AUTOSAR XML (schema 4-2-2)
package /ComponentTypes
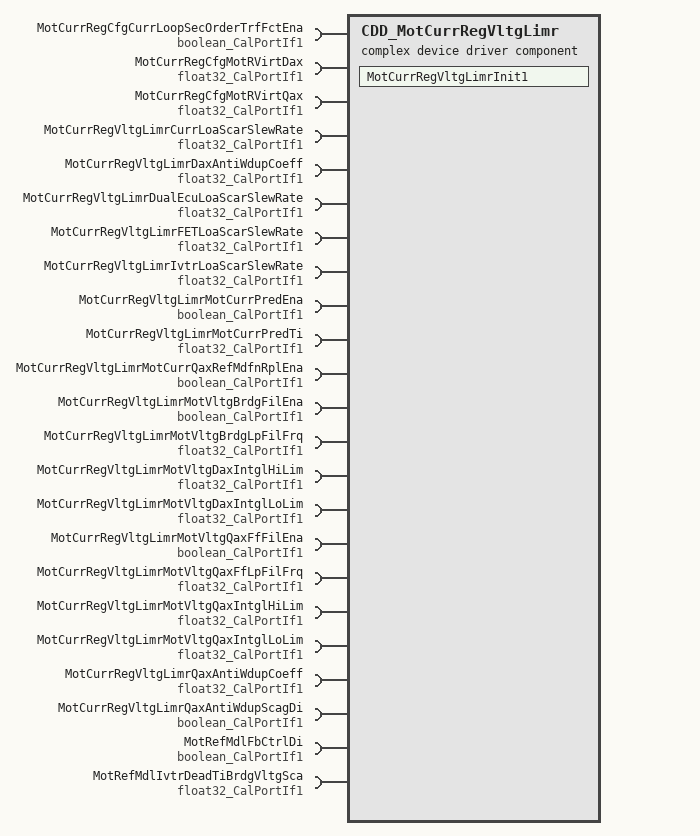
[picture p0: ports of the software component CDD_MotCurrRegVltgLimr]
  complex device driver sw component type CDD_MotCurrRegVltgLimr
    23 x require port:
      MotCurrRegCfgCurrLoopSecOrderTrfFctEna: parameter-require-com-spec{init-value=1, parameter=Logl}, required-interface=boolean_CalPortIf1
      MotCurrRegCfgMotRVirtDax: parameter-require-com-spec{init-value=0, parameter=Val}, required-interface=float32_CalPortIf1
      MotCurrRegCfgMotRVirtQax: parameter-require-com-spec{init-value=0, parameter=Val}, required-interface=float32_CalPortIf1
      MotCurrRegVltgLimrCurrLoaScarSlewRate: parameter-require-com-spec{init-value=100, parameter=Val}, required-interface=float32_CalPortIf1
      MotCurrRegVltgLimrDaxAntiWdupCoeff: parameter-require-com-spec{init-value=0, parameter=Val}, required-interface=float32_CalPortIf1
      MotCurrRegVltgLimrDualEcuLoaScarSlewRate: parameter-require-com-spec{init-value=100, parameter=Val}, required-interface=float32_CalPortIf1
      MotCurrRegVltgLimrFETLoaScarSlewRate: parameter-require-com-spec{init-value=100, parameter=Val}, required-interface=float32_CalPortIf1
      MotCurrRegVltgLimrIvtrLoaScarSlewRate: parameter-require-com-spec{init-value=100, parameter=Val}, required-interface=float32_CalPortIf1
      MotCurrRegVltgLimrMotCurrPredEna: parameter-require-com-spec{init-value=0, parameter=Logl}, required-interface=boolean_CalPortIf1
      MotCurrRegVltgLimrMotCurrPredTi: parameter-require-com-spec{init-value=0, parameter=Val}, required-interface=float32_CalPortIf1
      MotCurrRegVltgLimrMotCurrQaxRefMdfnRplEna: parameter-require-com-spec{init-value=0, parameter=Logl}, required-interface=boolean_CalPortIf1
      MotCurrRegVltgLimrMotVltgBrdgFilEna: parameter-require-com-spec{init-value=1, parameter=Logl}, required-interface=boolean_CalPortIf1
      MotCurrRegVltgLimrMotVltgBrdgLpFilFrq: parameter-require-com-spec{init-value=200, parameter=Val}, required-interface=float32_CalPortIf1
      MotCurrRegVltgLimrMotVltgDaxIntglHiLim: parameter-require-com-spec{init-value=9, parameter=Val}, required-interface=float32_CalPortIf1
      MotCurrRegVltgLimrMotVltgDaxIntglLoLim: parameter-require-com-spec{init-value=-4.5, parameter=Val}, required-interface=float32_CalPortIf1
      MotCurrRegVltgLimrMotVltgQaxFfFilEna: parameter-require-com-spec{init-value=1, parameter=Logl}, required-interface=boolean_CalPortIf1
      MotCurrRegVltgLimrMotVltgQaxFfLpFilFrq: parameter-require-com-spec{init-value=500, parameter=Val}, required-interface=float32_CalPortIf1
      MotCurrRegVltgLimrMotVltgQaxIntglHiLim: parameter-require-com-spec{init-value=14.5, parameter=Val}, required-interface=float32_CalPortIf1
      MotCurrRegVltgLimrMotVltgQaxIntglLoLim: parameter-require-com-spec{init-value=-14.5, parameter=Val}, required-interface=float32_CalPortIf1
      MotCurrRegVltgLimrQaxAntiWdupCoeff: parameter-require-com-spec{init-value=0, parameter=Val}, required-interface=float32_CalPortIf1
      MotCurrRegVltgLimrQaxAntiWdupScagDi: parameter-require-com-spec{init-value=0, parameter=Logl}, required-interface=boolean_CalPortIf1
      MotRefMdlFbCtrlDi: parameter-require-com-spec{init-value=0, parameter=Logl}, required-interface=boolean_CalPortIf1
      MotRefMdlIvtrDeadTiBrdgVltgSca: parameter-require-com-spec{init-value=1, parameter=Val}, required-interface=float32_CalPortIf1
    behavior CDD_MotCurrRegVltgLimr_InternalBehavior: data-type-mapping=Nexteer
      ar-typed-per-instance-memorys:
        39 x data, all with sw-calibration-access=READ-ONLY:
          AntiWdupCmdScaDax: type=float32
          AntiWdupCmdScaQax: type=float32
          CurrLoaScarPrev: type=float32
          dMotCurrRegVltgLimrAntiWdupCmdScaDax: type=float32
          dMotCurrRegVltgLimrAntiWdupCmdScaQax: type=float32
          dMotCurrRegVltgLimrMotCurrCmdErrDax: type=float32
          dMotCurrRegVltgLimrMotCurrCmdErrQax: type=float32
          dMotCurrRegVltgLimrMotCurrCmdScaDax: type=float32
          dMotCurrRegVltgLimrMotCurrCmdScaQax: type=float32
          dMotCurrRegVltgLimrMotVltgBrdgFild: type=float32
          dMotCurrRegVltgLimrMotVltgCmdFinal: type=float32
          dMotCurrRegVltgLimrMotVltgCmdPreLim: type=float32
          dMotCurrRegVltgLimrMotVltgDampgDax: type=float32
          dMotCurrRegVltgLimrMotVltgDampgQax: type=float32
          dMotCurrRegVltgLimrMotVltgDaxFb: type=float32
          dMotCurrRegVltgLimrMotVltgDaxIntglPreLim: type=float32
          dMotCurrRegVltgLimrMotVltgDecoupldFbDax: type=float32
          dMotCurrRegVltgLimrMotVltgDecoupldFbQax: type=float32
          dMotCurrRegVltgLimrMotVltgDircFbDax: type=float32
          dMotCurrRegVltgLimrMotVltgDircFbQax: type=float32
          dMotCurrRegVltgLimrMotVltgPreLimDax: type=float32
          dMotCurrRegVltgLimrMotVltgPreLimQax: type=float32
          dMotCurrRegVltgLimrMotVltgPropCmdDax: type=float32
          dMotCurrRegVltgLimrMotVltgPropCmdQax: type=float32
          dMotCurrRegVltgLimrMotVltgQaxFb: type=float32
          dMotCurrRegVltgLimrMotVltgQaxFfFild: type=float32
          dMotCurrRegVltgLimrMotVltgQaxIntglPreLim: type=float32
          dMotCurrRegVltgLimrMotVltgSatnIvsRat: type=float32
          dMotCurrRegVltgLimrMotVltgSatnRat: type=float32
          dMotCurrRegVltgLimrPhaAdvPreDly: type=float32
          DualEcuLoaScarPrev: type=float32
          FETLoaScarPrev: type=float32
          IvtrLoaScarPrev: type=float32
          MotCtrlMotVltgDaxPrev: type=float32
          MotCtrlMotVltgQaxPrev: type=float32
          MotVltgBrdgLpFil: type=FilLpRec1
          MotVltgIntglCmdDaxPrev: type=float32
          MotVltgIntglCmdQaxPrev: type=float32
          MotVltgQaxFfLpFil: type=FilLpRec1
      init event MotCurrRegVltgLimrInit1_InitEvent: start-on-event=MotCurrRegVltgLimrInit1
      port-api-options:
        enable-take-address=false, error-handling=NO-TRANSFORMER-ERROR-HANDLING, indirect-api=false, port=MotCurrRegCfgCurrLoopSecOrderTrfFctEna
        enable-take-address=false, error-handling=NO-TRANSFORMER-ERROR-HANDLING, indirect-api=false, port=MotCurrRegCfgMotRVirtQax
        enable-take-address=false, error-handling=NO-TRANSFORMER-ERROR-HANDLING, indirect-api=false, port=MotCurrRegVltgLimrCurrLoaScarSlewRate
        enable-take-address=false, error-handling=NO-TRANSFORMER-ERROR-HANDLING, indirect-api=false, port=MotCurrRegVltgLimrDaxAntiWdupCoeff
        enable-take-address=false, error-handling=NO-TRANSFORMER-ERROR-HANDLING, indirect-api=false, port=MotCurrRegVltgLimrDualEcuLoaScarSlewRate
        enable-take-address=false, error-handling=NO-TRANSFORMER-ERROR-HANDLING, indirect-api=false, port=MotCurrRegVltgLimrIvtrLoaScarSlewRate
        enable-take-address=false, error-handling=NO-TRANSFORMER-ERROR-HANDLING, indirect-api=false, port=MotCurrRegVltgLimrMotCurrPredEna
        enable-take-address=false, error-handling=NO-TRANSFORMER-ERROR-HANDLING, indirect-api=false, port=MotCurrRegVltgLimrMotCurrQaxRefMdfnRplEna
        enable-take-address=false, error-handling=NO-TRANSFORMER-ERROR-HANDLING, indirect-api=false, port=MotCurrRegVltgLimrMotVltgBrdgFilEna
        enable-take-address=false, error-handling=NO-TRANSFORMER-ERROR-HANDLING, indirect-api=false, port=MotCurrRegVltgLimrMotVltgBrdgLpFilFrq
        enable-take-address=false, error-handling=NO-TRANSFORMER-ERROR-HANDLING, indirect-api=false, port=MotCurrRegVltgLimrMotVltgDaxIntglHiLim
        enable-take-address=false, error-handling=NO-TRANSFORMER-ERROR-HANDLING, indirect-api=false, port=MotRefMdlIvtrDeadTiBrdgVltgSca
      runnable MotCurrRegVltgLimrInit1
  swc implementation CDD_MotCurrRegVltgLimr_Implementation: behavior=CDD_MotCurrRegVltgLimr_InternalBehavior
    code-descriptors:
      code Default: artifact-descriptors=autosar-engineering-object={short-label=Default, category=SWSRC}
